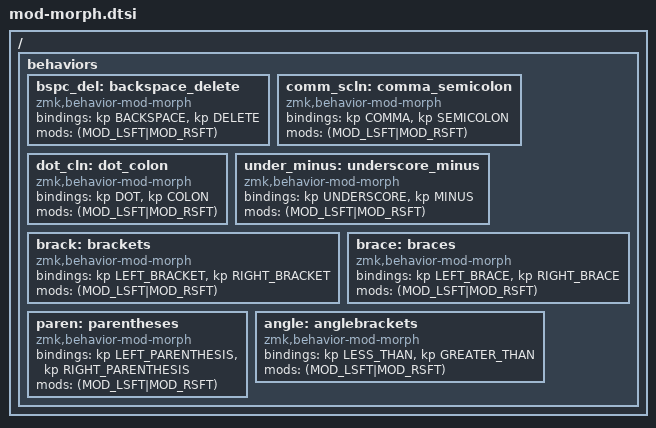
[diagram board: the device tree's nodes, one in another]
/ {
    behaviors {
		bspc_del: backspace_delete {
			compatible = "zmk,behavior-mod-morph";
			#binding-cells = <0>;
			bindings = <&kp BACKSPACE>, <&kp DELETE>;
			mods = <(MOD_LSFT|MOD_RSFT)>;
		};
		
		comm_scln: comma_semicolon {
			compatible = "zmk,behavior-mod-morph";
			#binding-cells = <0>;
			bindings = <&kp COMMA>, <&kp SEMICOLON>;
			mods = <(MOD_LSFT|MOD_RSFT)>;
		};

		dot_cln: dot_colon {
			compatible = "zmk,behavior-mod-morph";
			#binding-cells = <0>;
			bindings = <&kp DOT>, <&kp COLON>;
			mods = <(MOD_LSFT|MOD_RSFT)>;
		};
		
		under_minus: underscore_minus {
			compatible = "zmk,behavior-mod-morph";
			#binding-cells = <0>;
			bindings = <&kp UNDERSCORE>, <&kp MINUS>;
			mods = <(MOD_LSFT|MOD_RSFT)>;
		};

		brack: brackets {
			compatible = "zmk,behavior-mod-morph";
			#binding-cells = <0>;
			bindings = <&kp LEFT_BRACKET>, <&kp RIGHT_BRACKET>;
			mods = <(MOD_LSFT|MOD_RSFT)>;
		};

		brace: braces {
			compatible = "zmk,behavior-mod-morph";
			#binding-cells = <0>;
			bindings = <&kp LEFT_BRACE>, <&kp RIGHT_BRACE>;
			mods = <(MOD_LSFT|MOD_RSFT)>;
		};

		paren: parentheses {
			compatible = "zmk,behavior-mod-morph";
			#binding-cells = <0>;
			bindings = <&kp LEFT_PARENTHESIS>, <&kp RIGHT_PARENTHESIS>;
			mods = <(MOD_LSFT|MOD_RSFT)>;
		};

		angle: anglebrackets {
			compatible = "zmk,behavior-mod-morph";
			#binding-cells = <0>;
			bindings = <&kp LESS_THAN>, <&kp GREATER_THAN>;
			mods = <(MOD_LSFT|MOD_RSFT)>;
		};
	};
};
